VERSION ""

NS_ :

BS_:

BU_: VEHICLE

BO_ 16 GPS_Status: 8 Vector__XXX
 SG_ GPS_Status_OK : 0|8@1+ (1,0) [0|255] "" Vector__XXX

BO_ 7 TLOG: 8 Vector__XXX
 SG_ ComTime_Now : 0|64@1+ (1,0) [0|0] "" Vector__XXX

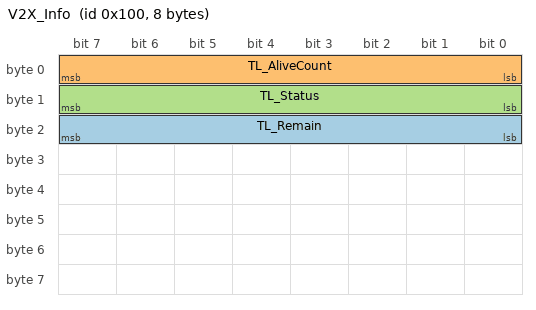
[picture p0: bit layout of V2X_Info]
BO_ 256 V2X_Info: 8 VEHICLE
 SG_ TL_Remain : 16|8@1+ (1,0) [0|4095] "-" Vector__XXX
 SG_ TL_AliveCount : 0|8@1+ (1,0) [0|4095] "-" Vector__XXX
 SG_ TL_Status : 8|8@1+ (1,0) [0|4095] "-"  VEHICLE

CM_ BO_ 256 "Vehicle Brake Pressure";
